NS_ :

BS_:

BO_ 274923520 DriverDoorStatus: 1 GMLAN
 SG_ DriverDoorOpened : 0|1@0+ (1,0) [0|0] ""  NEO

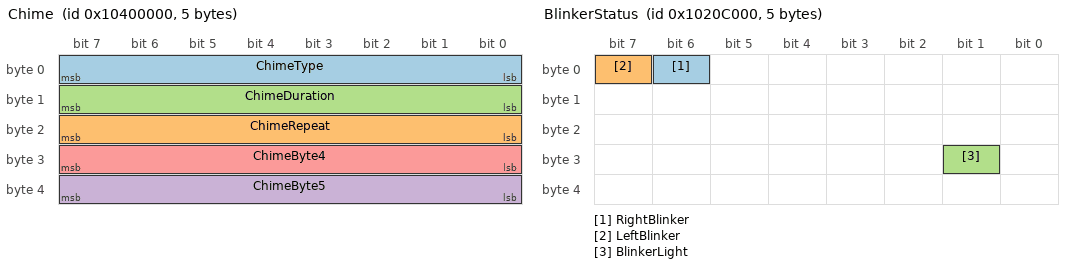
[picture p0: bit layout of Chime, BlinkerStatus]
BO_ 272629760 Chime: 5 NEO
 SG_ ChimeType : 7|8@0+ (1,0) [0|0] ""  GMLAN
 SG_ ChimeRepeat : 23|8@0+ (1,0) [0|0] ""  GMLAN
 SG_ ChimeDuration : 15|8@0+ (1,0) [0|0] ""  GMLAN
 SG_ ChimeByte5 : 39|8@0+ (1,0) [0|0] ""  GMLAN
 SG_ ChimeByte4 : 31|8@0+ (1,0) [0|0] ""  GMLAN

BO_ 270581760 BlinkerStatus: 5 GMLAN
 SG_ RightBlinker : 6|1@0+ (1,0) [0|0] ""  NEO
 SG_ LeftBlinker : 7|1@0+ (1,0) [0|0] ""  NEO
 SG_ BlinkerLight : 25|1@0+ (1,0) [0|0] ""  NEO

BO_ 270794752 SteeringWheelAngle: 8 GMLAN
 SG_ SteeringWheelAngle : 39|16@0- (0.0625,0) [-540|540] "deg"  NEO

BO_ 271368192 GearShifter: 8 GMLAN
 SG_ GearShifter : 17|2@0+ (1,0) [0|3] ""  NEO

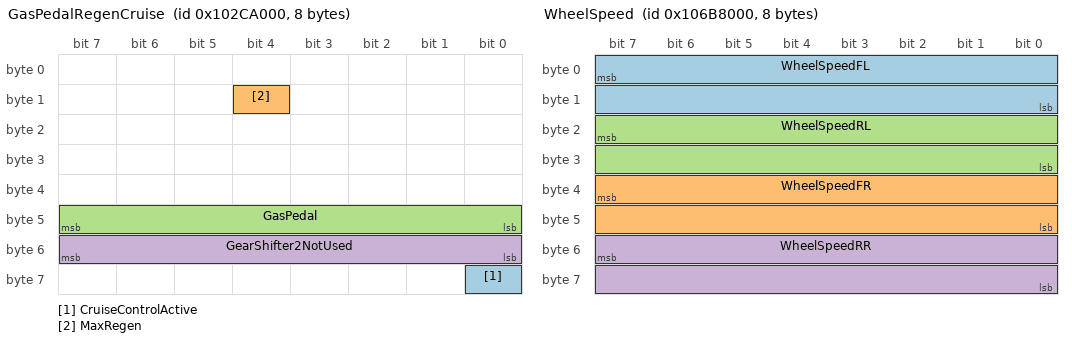
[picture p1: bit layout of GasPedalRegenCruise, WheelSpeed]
BO_ 271360000 GasPedalRegenCruise: 8 GMLAN
 SG_ CruiseControlActive : 56|1@0+ (1,0) [0|0] ""  GMLAN
 SG_ MaxRegen : 12|1@0+ (1,0) [0|1] ""  GMLAN,NEO
 SG_ GasPedal : 47|8@0+ (1,0) [0|254] ""  GMLAN,NEO
 SG_ GearShifter2NotUsed : 55|8@0+ (1,0) [0|255] ""  GMLAN,NEO

BO_ 270860288 BrakePedal: 2 GMLAN
 SG_ BrakeLevel : 2|2@0+ (1,0) [0|3] ""  NEO
 SG_ BrakeSensor : 15|8@0+ (1,0) [0|255] ""  NEO

BO_ 275480576 WheelSpeed: 8 GMLAN
 SG_ WheelSpeedFL : 7|16@0+ (0.01,0) [0|70] "yd/s"  NEO
 SG_ WheelSpeedFR : 39|16@0+ (0.01,0) [0|70] "yd/s"  NEO
 SG_ WheelSpeedRL : 23|16@0+ (0.01,0) [0|70] "yd/s"  NEO
 SG_ WheelSpeedRR : 55|16@0+ (0.01,0) [0|70] "yd/s"  NEO

BO_ 270598144 VehicleSpeed: 8 GMLAN
 SG_ VehicleSpeed1 : 7|16@0+ (0.01,0) [0|100] "mph"  NEO
 SG_ VehicleSpeed2 : 39|16@0+ (0.01,0) [0|100] "mph"  NEO

BO_ 276135936 CruiseButtons: 3 GMLAN
 SG_ CruiseButtons : 3|3@0+ (1,0) [0|12] ""  NEO

BO_ 276127744 CruiseButtons2: 1 GMLAN
 SG_ LKAGapButton : 1|2@0+ (1,0) [0|2] ""  NEO

BO_ 275955897 LeftRadar: 2 GMLAN
 SG_ BSM_Indicator_Light : 4|1@0+ (1,0) [0|1] "" XXX

BO_ 275980379 RightRadar: 2 GMLAN
 SG_ BSM_Indicator_Light : 0|1@0+ (1,0) [0|1] "" XXX

BA_DEF_  "UseGMParameterIDs" INT 0 0;
BA_DEF_  "ProtocolType" STRING ;
BA_DEF_  "BusType" STRING ;
BA_DEF_DEF_  "UseGMParameterIDs" 1;
BA_DEF_DEF_  "ProtocolType" "GMLAN";
BA_DEF_DEF_  "BusType" "";
BA_ "BusType" "CAN";
BU_: XXX

CM_ SG_ 544 track_id "for message a_1 track_id is always 1, similar for other messages and track_id";
CM_ SG_ 544 REL_ACCEL "perhaps REL_ACCEL because it responds faster and before REL_SPEED";
CM_ SG_ 544 sig2 "perhaps distance to object. LONG_DIST or REL_ACCEL or REL_SPEED";
CM_ SG_ 576 zeros "not always zero, sometimes has value when another car changes lanes";
VAL_ 295 GEAR 0 "P" 1 "R" 2 "N" 3 "D" 4 "B" ;
VAL_ 466 CRUISE_STATE 11 "timer_3sec" 10 "setspeeddown" 9 "setspeedup" 8 "active" 7 "standstill" 1 "off" 0 "off";
VAL_ 610 STATE 5 "override" 3 "enabled" 1 "disabled" ;
VAL_ 610 LKA_STATE 50 "temporary_fault" ;
VAL_ 614 STATE 3 "enabled" 1 "disabled" ;
VAL_ 614 DIRECTION_CMD 3 "right" 2 "center" 1 "left" ;
VAL_ 1556 TURN_SIGNALS 3 "none" 2 "right" 1 "left" ;
VAL_ 467 LOW_SPEED_LOCKOUT 2 "low speed locked" 1 "ok" ;
VAL_ 921 CRUISE_CONTROL_STATE 2 "disabled" 11 "hold" 10 "hold_waiting_user_cmd" 6 "enabled" 5 "faulted" ;
VAL_ 1042 BARRIERS 3 "both" 2 "right" 1 "left" 0 "none" ;
VAL_ 1042 RIGHT_LINE 3 "orange" 2 "double" 1 "solid" 0 "none" ;
VAL_ 1042 LEFT_LINE 3 "orange" 2 "double" 1 "solid" 0 "none" ;
VAL_ 1042 LDA_ALERT 3 "hold with continuous beep" 2 "LDA unavailable" 1 "hold" 0 "none" ;
